# CODEC0_VPU register map
Vendor: Texas Instruments
Peripheral module from a debugger description file (folder am62A).
Registers are 32-bit, read-only, reset 0x0 unless marked. A register's access mark holds for its fields unless they carry their own. Offsets are as the file gives them; lines under a group give offsets from that group; [hi:lo] are bit positions; {n}, {i} and the like mark numbered series; 'fields as' and 'values as' point back to an identical list; <NAME> marks a mode.

## CODEC0_VPU
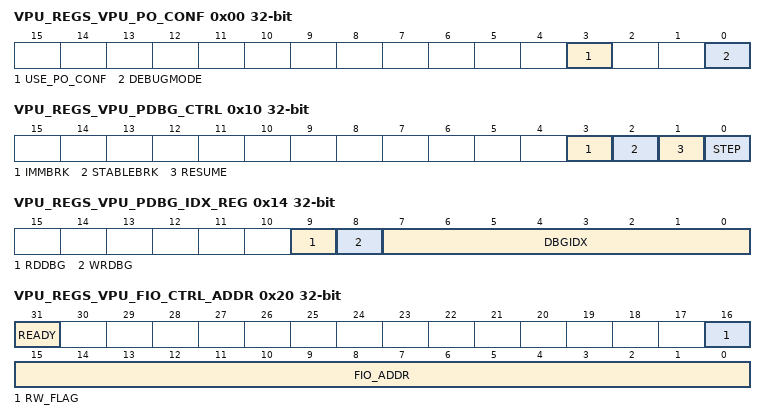
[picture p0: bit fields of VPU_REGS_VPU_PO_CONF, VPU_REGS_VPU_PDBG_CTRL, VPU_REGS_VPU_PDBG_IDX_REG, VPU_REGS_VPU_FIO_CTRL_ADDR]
0x00 VPU_REGS_VPU_PO_CONF wo — Power On Configuration
  [3] USE_PO_CONF — Host processor should set 0 when initialization
  [0] DEBUGMODE — Power on Debug Mode
0x04 VPU_REGS_VCPU_CUR_PC — Current PC
  [31:0] CUR_PC — PC value represents the address of instruction which is executed in V-CPU
0x08 VPU_REGS_VCPU_CUR_LR — Current LR
  [31:0] CUR_LR — Current LR (Link Register) to find out caller address
0x0C VPU_REGS_VPU_PDBG_STEP_MASK rw — V-CPU Debugger Step Mask
  [0] STEP_MASK_ENABLE — Interrupt Disable at step for debugger
0x10 VPU_REGS_VPU_PDBG_CTRL wo — V-CPU Debugger Control
  [3] IMMBRK — Immediate break
  [2] STABLEBRK — Stable break
  [1] RESUME
  [0] STEP
0x14 VPU_REGS_VPU_PDBG_IDX_REG wo — V-CPU Debugger Index
  [9] RDDBG — Read Operation Request
  [8] WRDBG — Write Operation Request
  [7:0] DBGIDX — Debug Index
0x18 VPU_REGS_VPU_PDBG_WDATA_REG wo — V-CPU Debugger Write Data
  [31:0] VPU_PDBG_WDATA_REG — Write data to the debugger
0x1C VPU_REGS_VPU_PDBG_RDATA_REG wo — V-CPU Debugger Read Data
  [31:0] VPU_PDBG_RDATA_REG — Read data to the debugger
0x20 VPU_REGS_VPU_FIO_CTRL_ADDR access per field — FastIO Control/Address
  [31] READY ro — Ready for the transaction
  [16] RW_FLAG wo — Read/Write transaction control
  [15:0] FIO_ADDR wo — FIO Address
0x24 VPU_REGS_VPU_FIO_DATA rw — FastIO Data
  [31:0] FIO_DATA
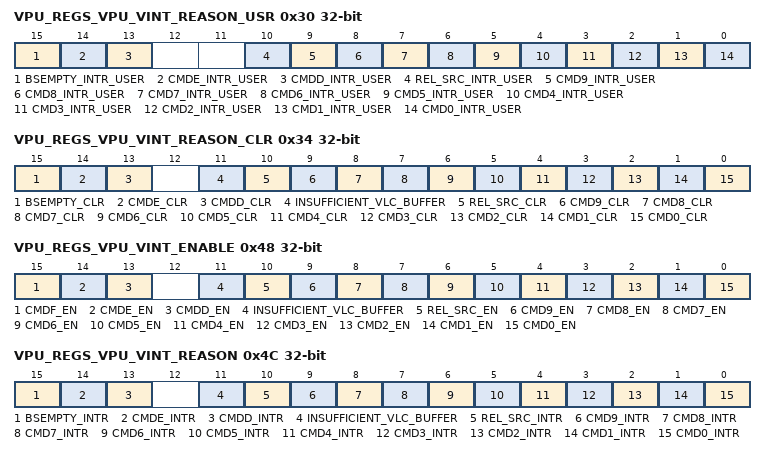
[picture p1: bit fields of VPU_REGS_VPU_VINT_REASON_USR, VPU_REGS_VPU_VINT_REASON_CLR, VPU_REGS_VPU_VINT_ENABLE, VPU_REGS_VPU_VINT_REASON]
0x30 VPU_REGS_VPU_VINT_REASON_USR rw — Interrupt Reason User
  [15] BSEMPTY_INTR_USER — Bitstream empty feeding request interrupt
  [14] CMDE_INTR_USER — QUERY command done interrupt
  [13] CMDD_INTR_USER — Low latency interrupt. Valid if low latency feature is enabled.
  [10] REL_SRC_INTR_USER — Release source buffer interrupt. Valid only if feature of release src buf is enabled
  [9] CMD9_INTR_USER — ENC_SET_PARAM command done interrupt
  [8] CMD8_INTR_USER — DEC_PIC/ENC_PIC command done interrupt
  [7] CMD7_INTR_USER — SET_FRAMEBUFFER command done interrupt
  [6] CMD6_INTR_USER — INIT_SEQ command done interrupt
  [5] CMD5_INTR_USER — DESTROY_INSTANCE command done interrupt
  [4] CMD4_INTR_USER — FLUSH_INSTANCE command done interrupt
  [3] CMD3_INTR_USER — CREATE_INSTANCE command done interrupt
  [2] CMD2_INTR_USER — SLEEP_VPU command done interrupt
  [1] CMD1_INTR_USER — WAKE_VPU command done interrupt
  [0] CMD0_INTR_USER — INIT_VPU command done interrupt
0x34 VPU_REGS_VPU_VINT_REASON_CLR — Interrupt Reason Clear
  [15] BSEMPTY_CLR — Bitstream empty bitstream feeding request interrupt clear
  [14] CMDE_CLR — QUERY command done interrupt clear
  [13] CMDD_CLR — Low Latency interrupt clear. Valid only if low latency feature is enabled
  [11] INSUFFICIENT_VLC_BUFFER — VLC buffer realloc request interrupt enable. Valid only if VLC BUFFER CUSTOMIZATION features in VPU
  [10] REL_SRC_CLR — Release source buffer interrupt. Valid only if the feature of release src buf is enabled
  [9] CMD9_CLR — ENC_SET_PARAM command done interrupt clear
  [8] CMD8_CLR — DEC_PIC/ENC_PIC command done interrupt clear
  [7] CMD7_CLR — SET_FRAMEBUFFER command done interrupt clear
  [6] CMD6_CLR — INIT_SEQ command done interrupt clear
  [5] CMD5_CLR — DESTROY_INSTANCE command done interrupt clear
  [4] CMD4_CLR — FLSUH_INSTANCE command done interrupt clear
  [3] CMD3_CLR — CREATE_INSTANCE command done interrupt clear
  [2] CMD2_CLR — SLEEP_VPU command done interrupt clear
  [1] CMD1_CLR — WAKE_VPU command done interrupt clear
  [0] CMD0_CLR — INIT_VPU command done interrupt clear
0x38 VPU_REGS_VPU_HOST_INT_REQ rw — Host Interrupt Request
  [0] HINTREQ — If this is set to 1, an interrupt named HOST interrupt is sent to VPU.
0x3C VPU_REGS_VPU_VINT_CLEAR — VPU Interrupt Clear
  [0] VINTREQ — Clear VPU interrupt.
0x40 VPU_REGS_VPU_HINT_CLEAR rw — Host Interrupt Clear
  [0] HINTCLR — Check Host Command Interrupt is cleared.
0x44 VPU_REGS_VPU_VPU_INT_STS — VPU Interrupt Status
  [0] VPU_VPU_INT_STS — Interrupt Status
0x48 VPU_REGS_VPU_VINT_ENABLE rw — VPU Interrupt Enable
  [15] CMDF_EN — UPDATE_BS command done interrupt enable
  [14] CMDE_EN — QUERY command done interrupt enable
  [13] CMDD_EN — Low latency interrupt enable
  [11] INSUFFICIENT_VLC_BUFFER — VLC Buffer Realloc request interrupt enable. Valid only if VLC BUFFER CUSTOMIZATION feature in VPU
  [10] REL_SRC_EN — Release Source buffer interrupt enable. Valid only if feature of release src buf is enabled.
  [9] CMD9_EN — ENC_SET_PARAM command done interrupt enable
  [8] CMD8_EN — DEC_PIC/ENC_PIC command done interrupt enable
  [7] CMD7_EN — SET_FRAMEBUFFER command done interrupt enable
  [6] CMD6_EN — SET_FRAMEBUFFER command done interrupt enable
  [5] CMD5_EN — DESTROY_INSTANCE command done interrupt enable
  [4] CMD4_EN — FLUSH INSTANCE command done interrupt enable
  [3] CMD3_EN — CREATE INSTANCE command done interrupt enable
  [2] CMD2_EN — SLEEP_VPU command done interrupt enable
  [1] CMD1_EN — WAKE_VPU command done interrupt enable
  [0] CMD0_EN — INIT_VPU command done interrupt enable
0x4C VPU_REGS_VPU_VINT_REASON rw — VPU Interrupt Reason
  [15] BSEMPTY_INTR — Bitstream empty ,bitstream feeding request.
  [14] CMDE_INTR — QUERY command done interrupt
  [13] CMDD_INTR — Low latency interrupt
  [11] INSUFFICIENT_VLC_BUFFER — VLC Buffer realloc request interrupt. Valid only if VLC BUFFER CUSTOMIZATION feature in VPU
  [10] REL_SRC_INTR — Release source buffer Interrupt. Valid only if the feature of release src buf is enabled
  [9] CMD9_INTR — ENC_SET_PARAM command done interrupt
  [8] CMD8_INTR — DEC_PIC/ENC_PIC command done interrupt
  [7] CMD7_INTR — SET_FRAMEBUFFER command done interrupt
  [6] CMD6_INTR — INIT_SEQ command done interrupt
  [5] CMD5_INTR — DESTROY_INSTANCE command done interrupt
  [4] CMD4_INTR — FLUSH_INSTANCE command done interrupt
  [3] CMD3_INTR — CREATE_INSTANCE command done interrupt
  [2] CMD2_INTR — SLEEP_VPU command done interrupt
  [1] CMD1_INTR — WAKE_VPU command done interrupt
  [0] CMD0_INTR — INIT_VPU command done interrupt
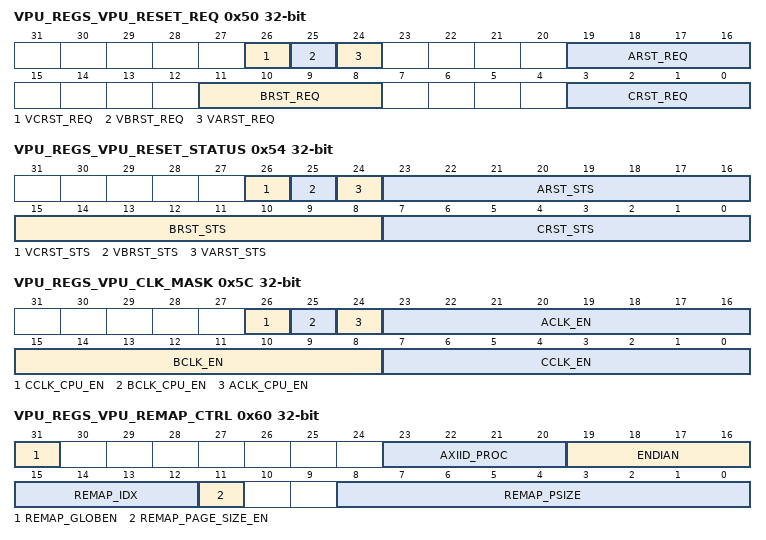
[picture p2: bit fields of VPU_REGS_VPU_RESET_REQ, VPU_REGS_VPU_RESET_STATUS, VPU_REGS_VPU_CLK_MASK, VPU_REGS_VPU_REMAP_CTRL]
0x50 VPU_REGS_VPU_RESET_REQ rw — VPU Reset Request
  [26] VCRST_REQ — CCLK domain for V-CPU Reset request
  [25] VBRST_REQ — BCLK domain for V-CPU Reset request
  [24] VARST_REQ — ACLK domain for V-CPU Reset request
  [19:16] ARST_REQ — ACLK domain reset request for each vCORE
  [11:8] BRST_REQ — BCLK domain reset request for each vCORE
  [3:0] CRST_REQ — CCLK domain reset request for each vCORE
0x54 VPU_REGS_VPU_RESET_STATUS — VPU Reset Status
  [26] VCRST_STS — CCLK domain for V-CPU reset status
  [25] VBRST_STS — BCLK domain for V-CPU reset status
  [24] VARST_STS — ACLK domain for V-CPU reset status
  [23:16] ARST_STS — ACLK domain for each V-Core reset status
  [15:8] BRST_STS — BCLK domain for each V-Core reset status
  [7:0] CRST_STS — CCLK domain for each V-Core reset status
0x58 VPU_REGS_VCPU_RESTART wo — V-CPU Restart Request
  [0] VCPU_RESTART_FIELD — This register restarts V-CPU from the reset vector without clearing H/W logic
0x5C VPU_REGS_VPU_CLK_MASK rw — VPU Clock Control
  [26] CCLK_CPU_EN — CCLK domain for V-CPU Gating
  [25] BCLK_CPU_EN — BCLK domain for V-CPU Gating
  [24] ACLK_CPU_EN — ACLK domain for V-CPU Gating
  [23:16] ACLK_EN — ACLK domain for V-Core Gating
  [15:8] BCLK_EN — BCLK domain for V-Core Gating
  [7:0] CCLK_EN — CCLK domain for V-Core Gating
0x60 VPU_REGS_VPU_REMAP_CTRL access per field — Remap Control
  [31] REMAP_GLOBEN ro — Set 1 if you want to change the [30:12] part of this register
  [23:20] AXIID_PROC rw — Upper AXI-ID for processor bus to distinguish guest OS
  [19:16] ENDIAN ro — Endianness for memory access
  [15:12] REMAP_IDX rw — Remap index
  [11] REMAP_PAGE_SIZE_EN rw — Set 1 if you want to change the REMAP_PSIZE field
  [8:0] REMAP_PSIZE rw — Remap Page Size
0x64 VPU_REGS_VPU_REMAP_VADDR rw — Remap Virutal Address
  [31:12] VPU_REMAP_VADDR — Remap region base address in virtual address space.
0x68 VPU_REGS_VPU_REMAP_PADDR rw — Remap Physical Address
  [31:12] VPU_REMAP_PADDR — Real address (physical address) as a pair of virtual address.
0x6C VPU_REGS_VPU_REMAP_CORE_START rw — VPU Start Request
  [0] VPU_REMAP_CORE_START — It starts VPU after initial setting has been done.
0x70 VPU_REGS_VPU_BUSY_STATUS rw — VPU Busy Status
  [0] VPU_BUSY_STATUS — Command Reentrance Check [0]
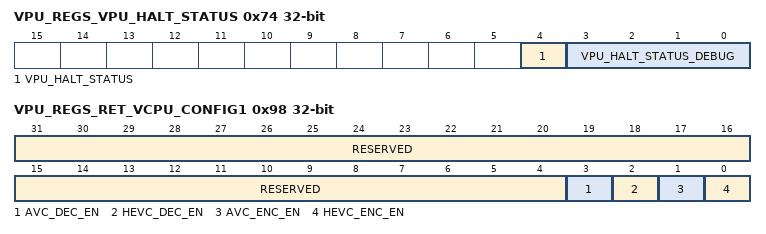
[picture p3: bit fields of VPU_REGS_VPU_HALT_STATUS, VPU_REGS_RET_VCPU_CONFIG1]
0x74 VPU_REGS_VPU_HALT_STATUS — VPU Halt Status
  [4] VPU_HALT_STATUS — V-CPU is on the HALT Status
  [3:0] VPU_HALT_STATUS_DEBUG — For debugging
0x78 VPU_REGS_VPU_VCPU_STATUS — VCPU STATUS
  [14:0] VPU_VCPU_STATUS — If [15:0] is 0x0040, V-CPU is on the halt status.Thus, the value returns 0x40, power for VPU can be turnned-off
0x7C VPU_REGS_RSVD access not given reset not defined — RSVD
0x80 VPU_REGS_RET_FIO_STATUS — RETURN FIO STATUS
  [31:0] RESERVED — RET FIO STATUS
0x90 VPU_REGS_RET_PRODUCT_NAME — HW product name
  [2:0] HW_NAME — VPU hardware product name
0x94 VPU_REGS_RET_PRODUCT_VERSION — HW product version
  [2:0] HW_VERSION — VPU hardware product version
0x98 VPU_REGS_RET_VCPU_CONFIG0 — Configuration Information 0
  [31:0] RESERVED
0x98 VPU_REGS_RET_VCPU_CONFIG1 — Configuration Information 0
  [31:4] RESERVED — Configuration Information 0
  [3] AVC_DEC_EN — AVC decoder Enable
  [2] HEVC_DEC_EN — HEVC decoder Enable
  [1] AVC_ENC_EN — AVC encoder Enable
  [0] HEVC_ENC_EN — HEVC encoder Enable
0xA0 VPU_REGS_RET_CODEC_STD — Standard Definition
  [31:0] CODEC_STD — General Configuration Information - Internal Use only
0xA4 VPU_REGS_RET_CONF_DATE — Configuration Date
  [31:0] HW_DATE — The date that the hardware has been configured in YYYYMMDD. Internal Use only.
0xA8 VPU_REGS_RET_CONF_REVISION — The revision of H/W configuration
  [31:0] HW_VERSION — Revision Number when the hardware has been configured. Internal Use only
0xAC VPU_REGS_RET_CONF_TYPE — The define value of H/W configuration
  [31:0] HW_TYPE — The define value used in hardware configuration. Internal Use only.
{0xB0+4i} VPU_REGS_RET_VCORE{i}_CFG (i=0..3) — Configuration Information of VCORE{i}
  [31:0] CONFIG_VCORE{i} — The VCORE{i} configuration information. Internal Use only
0xC0 VPU_REGS_VPU_RET_VCORE_PRESET — Number of VCOREs present
  [3:0] VCORE_PRESENT — Each bit represent turn-on VCORE
